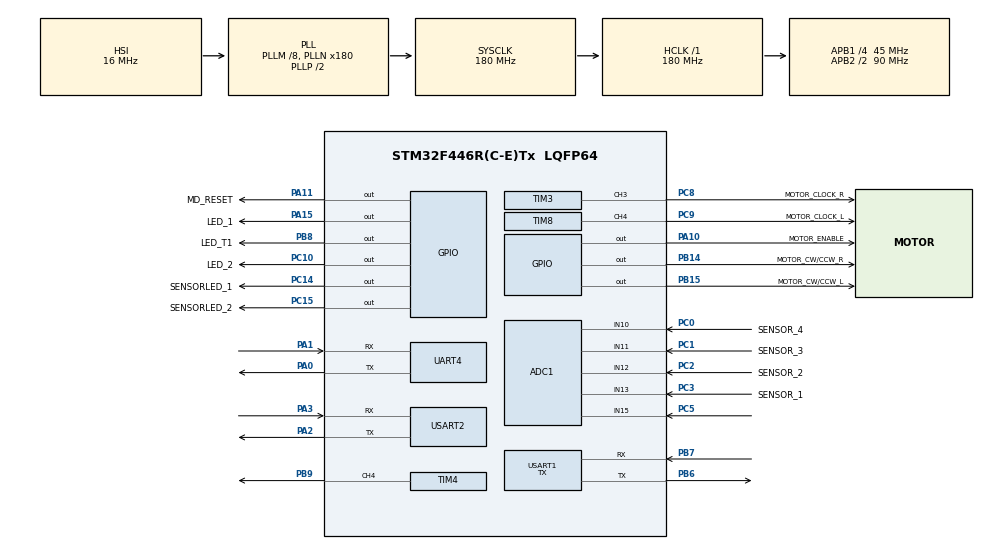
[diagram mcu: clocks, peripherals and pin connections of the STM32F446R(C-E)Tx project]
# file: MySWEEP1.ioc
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ADC1.Channel-0\#ChannelRegularConversion=ADC_CHANNEL_15
ADC1.Channel-1\#ChannelRegularConversion=ADC_CHANNEL_13
ADC1.Channel-2\#ChannelRegularConversion=ADC_CHANNEL_12
ADC1.Channel-3\#ChannelRegularConversion=ADC_CHANNEL_11
ADC1.Channel-4\#ChannelRegularConversion=ADC_CHANNEL_10
ADC1.ContinuousConvMode=ENABLE
ADC1.EnableAnalogWatchDog=false
ADC1.InjNumberOfConversion=0
ADC1.NbrOfConversion=5
ADC1.NbrOfConversionFlag=1
ADC1.Rank-0\#ChannelRegularConversion=1
ADC1.Rank-1\#ChannelRegularConversion=2
ADC1.Rank-2\#ChannelRegularConversion=3
ADC1.Rank-3\#ChannelRegularConversion=4
ADC1.Rank-4\#ChannelRegularConversion=5
ADC1.SamplingTime-0\#ChannelRegularConversion=ADC_SAMPLETIME_3CYCLES
ADC1.SamplingTime-1\#ChannelRegularConversion=ADC_SAMPLETIME_3CYCLES
ADC1.SamplingTime-2\#ChannelRegularConversion=ADC_SAMPLETIME_3CYCLES
ADC1.SamplingTime-3\#ChannelRegularConversion=ADC_SAMPLETIME_3CYCLES
ADC1.SamplingTime-4\#ChannelRegularConversion=ADC_SAMPLETIME_3CYCLES
ADC1.ScanConvMode=ENABLE
ADC1.master=1
Dma.ADC1.0.Direction=DMA_PERIPH_TO_MEMORY
Dma.ADC1.0.FIFOMode=DMA_FIFOMODE_DISABLE
Dma.ADC1.0.Instance=DMA2_Stream0
Dma.ADC1.0.MemDataAlignment=DMA_MDATAALIGN_HALFWORD
Dma.ADC1.0.MemInc=DMA_MINC_ENABLE
Dma.ADC1.0.Mode=DMA_NORMAL
Dma.ADC1.0.PeriphDataAlignment=DMA_PDATAALIGN_HALFWORD
Dma.ADC1.0.PeriphInc=DMA_PINC_DISABLE
Dma.ADC1.0.Priority=DMA_PRIORITY_LOW
Dma.Request0=ADC1
Mcu.Family=STM32F4
Mcu.Name=STM32F446R(C-E)Tx
Mcu.Package=LQFP64
NVIC.ADC_IRQn=true\:0\:0\:false\:false\:true\:true\:true\:true
NVIC.DMA2_Stream0_IRQn=true\:2\:0\:true\:false\:true\:false\:true\:true
NVIC.PriorityGroup=NVIC_PRIORITYGROUP_4
NVIC.TIM3_IRQn=true\:0\:0\:false\:false\:true\:true\:true\:true
NVIC.TIM6_DAC_IRQn=true\:2\:0\:true\:false\:true\:true\:true\:true
NVIC.UART4_IRQn=true\:1\:0\:true\:false\:true\:true\:true\:true
PA0-WKUP.Mode=Asynchronous
PA0-WKUP.Signal=UART4_TX
PA1.Mode=Asynchronous
PA1.Signal=UART4_RX
PA10.GPIO_Label=MOTOR_ENABLE
PA10.Signal=GPIO_Output
PA11.GPIO_Label=MD_RESET
PA11.Signal=GPIO_Output
PA15.GPIO_Label=LED_1
PA15.Signal=GPIO_Output
PA2.Mode=Asynchronous
PA2.Signal=USART2_TX
PA3.Mode=Asynchronous
PA3.Signal=USART2_RX
PB14.GPIO_Label=MOTOR_CW/CCW_R
PB14.Signal=GPIO_Output
PB15.GPIO_Label=MOTOR_CW/CCW_L
PB15.Signal=GPIO_Output
PB6.Mode=Asynchronous
PB6.Signal=USART1_TX
PB7.Mode=Asynchronous
PB7.Signal=USART1_RX
PB8.GPIO_Label=LED_T1
PB8.Signal=GPIO_Output
PB9.Signal=S_TIM4_CH4
PC0.GPIO_Label=SENSOR_4
PC0.Signal=ADCx_IN10
PC1.GPIO_Label=SENSOR_3
PC1.Signal=ADCx_IN11
PC10.GPIO_Label=LED_2
PC10.Signal=GPIO_Output
PC14-OSC32_IN.GPIO_Label=SENSORLED_1
PC14-OSC32_IN.Signal=GPIO_Output
PC15-OSC32_OUT.GPIO_Label=SENSORLED_2
PC15-OSC32_OUT.Signal=GPIO_Output
PC2.GPIO_Label=SENSOR_2
PC2.Signal=ADCx_IN12
PC3.GPIO_Label=SENSOR_1
PC3.Signal=ADCx_IN13
PC5.Signal=ADCx_IN15
PC8.GPIO_Label=MOTOR_CLOCK_R
PC8.Signal=S_TIM3_CH3
PC9.GPIO_Label=MOTOR_CLOCK_L
PC9.Signal=S_TIM8_CH4
PH0-OSC_IN.Mode=HSE-External-Oscillator
PH0-OSC_IN.Signal=RCC_OSC_IN
PH1-OSC_OUT.Mode=HSE-External-Oscillator
PH1-OSC_OUT.Signal=RCC_OSC_OUT
ProjectManager.HeapSize=0x200
ProjectManager.StackSize=0x400
ProjectManager.TargetToolchain=STM32CubeIDE
RCC.AHBFreq_Value=180000000
RCC.APB1CLKDivider=RCC_HCLK_DIV4
RCC.APB1Freq_Value=45000000
RCC.APB1TimFreq_Value=90000000
RCC.APB2CLKDivider=RCC_HCLK_DIV2
RCC.APB2Freq_Value=90000000
RCC.APB2TimFreq_Value=180000000
RCC.CortexFreq_Value=180000000
RCC.HCLKFreq_Value=180000000
RCC.PLLM=8
RCC.PLLN=180
RCC.SYSCLKFreq_VALUE=180000000
RCC.SYSCLKSource=RCC_SYSCLKSOURCE_PLLCLK
RCC.USBFreq_Value=180000000
RCC.VCOOutputFreq_Value=360000000
SH.ADCx_IN10.0=ADC1_IN10,IN10
SH.ADCx_IN11.0=ADC1_IN11,IN11
SH.ADCx_IN12.0=ADC1_IN12,IN12
SH.ADCx_IN13.0=ADC1_IN13,IN13
SH.ADCx_IN15.0=ADC1_IN15,IN15
SH.S_TIM3_CH3.0=TIM3_CH3,PWM Generation3 CH3
SH.S_TIM4_CH4.0=TIM4_CH4,PWM Generation4 CH4
SH.S_TIM8_CH4.0=TIM8_CH4,PWM Generation4 CH4
TIM3.Channel-PWM\ Generation3\ CH3=TIM_CHANNEL_3
TIM3.Period=10000-1
TIM3.Prescaler=8-1
TIM3.Pulse-PWM\ Generation3\ CH3=5000-1
TIM4.Channel-PWM\ Generation4\ CH4=TIM_CHANNEL_4
TIM4.Period=100
TIM6.Period=1000-1
TIM6.Prescaler=90-1
TIM8.Channel-PWM\ Generation4\ CH4=TIM_CHANNEL_4
TIM8.Period=10000-1
TIM8.Prescaler=16-1
TIM8.Pulse-PWM\ Generation4\ CH4=5000-1
UART4.VirtualMode=Asynchronous
USART1.Mode=MODE_TX
USART1.VirtualMode=VM_ASYNC
USART2.VirtualMode=VM_ASYNC
VP_TIM6_VS_ClockSourceINT.Mode=Enable_Timer
board=custom

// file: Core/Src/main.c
/* USER CODE BEGIN Header */
/**
 ******************************************************************************
 * @file           : main.c
 * @brief          : Main program body
 ******************************************************************************
 * @attention
 *
 * Copyright (c) 2026 STMicroelectronics.
 * All rights reserved.
 *
 * This software is licensed under terms that can be found in the LICENSE file
 * in the root directory of this software component.
 * If no LICENSE file comes with this software, it is provided AS-IS.
 *
 ******************************************************************************
 */
/* USER CODE END Header */
#include "main.h"
#include "adc.h"
#include "dma.h"
#include "tim.h"
#include "usart.h"
#include "gpio.h"

/* USER CODE BEGIN Includes */
#include "app.h"
#include "drv_link.h"
/* USER CODE END Includes */

void SystemClock_Config(void);

int main(void)
{

  /* MCU Configuration--------------------------------------------------------*/

  /* Reset of all peripherals, Initializes the Flash interface and the Systick. */
  HAL_Init();

  /* Configure the system clock */
  SystemClock_Config();

  /* Initialize all configured peripherals */
  MX_GPIO_Init();
  MX_DMA_Init();
  MX_ADC1_Init();
  MX_TIM6_Init();
  MX_UART4_Init();
  MX_USART2_UART_Init();
  MX_TIM4_Init();
  MX_USART1_UART_Init();
  MX_TIM3_Init();
  MX_TIM8_Init();
  /* USER CODE BEGIN 2 */
  app_init();
  /* USER CODE END 2 */

  /* Infinite loop */
  /* USER CODE BEGIN WHILE */
  while (1)
  {
    app_loop();
    /* USER CODE END WHILE */

	}
}

void SystemClock_Config(void)
{
  RCC_OscInitTypeDef RCC_OscInitStruct = {0};
  RCC_ClkInitTypeDef RCC_ClkInitStruct = {0};

  /** Configure the main internal regulator output voltage
  */
  __HAL_RCC_PWR_CLK_ENABLE();
  __HAL_PWR_VOLTAGESCALING_CONFIG(PWR_REGULATOR_VOLTAGE_SCALE1);

  /** Initializes the RCC Oscillators according to the specified parameters
  * in the RCC_OscInitTypeDef structure.
  */
  RCC_OscInitStruct.OscillatorType = RCC_OSCILLATORTYPE_HSI;
  RCC_OscInitStruct.HSIState = RCC_HSI_ON;
  RCC_OscInitStruct.HSICalibrationValue = RCC_HSICALIBRATION_DEFAULT;
  RCC_OscInitStruct.PLL.PLLState = RCC_PLL_ON;
  RCC_OscInitStruct.PLL.PLLSource = RCC_PLLSOURCE_HSI;
  RCC_OscInitStruct.PLL.PLLM = 8;
  RCC_OscInitStruct.PLL.PLLN = 180;
  RCC_OscInitStruct.PLL.PLLP = RCC_PLLP_DIV2;
  RCC_OscInitStruct.PLL.PLLQ = 2;
  RCC_OscInitStruct.PLL.PLLR = 2;
  if (HAL_RCC_OscConfig(&RCC_OscInitStruct) != HAL_OK)
  {
    Error_Handler();
  }

  /** Activate the Over-Drive mode
  */
  if (HAL_PWREx_EnableOverDrive() != HAL_OK)
  {
    Error_Handler();
  }

  /** Initializes the CPU, AHB and APB buses clocks
  */
  RCC_ClkInitStruct.ClockType = RCC_CLOCKTYPE_HCLK|RCC_CLOCKTYPE_SYSCLK
                              |RCC_CLOCKTYPE_PCLK1|RCC_CLOCKTYPE_PCLK2;
  RCC_ClkInitStruct.SYSCLKSource = RCC_SYSCLKSOURCE_PLLCLK;
  RCC_ClkInitStruct.AHBCLKDivider = RCC_SYSCLK_DIV1;
  RCC_ClkInitStruct.APB1CLKDivider = RCC_HCLK_DIV4;
  RCC_ClkInitStruct.APB2CLKDivider = RCC_HCLK_DIV2;

  if (HAL_RCC_ClockConfig(&RCC_ClkInitStruct, FLASH_LATENCY_5) != HAL_OK)
  {
    Error_Handler();
  }
}

/* USER CODE BEGIN 4 */
void HAL_UART_RxCpltCallback(UART_HandleTypeDef *huart) {
  if (huart->Instance == UART4) {
    link_on_rx();
  }
}

void HAL_UART_ErrorCallback(UART_HandleTypeDef *huart) {
  if (huart->Instance == UART4) {
    link_on_error();
  }
}

/* USER CODE END 4 */

void Error_Handler(void)
{
	__disable_irq();
	while (1) {
	}
}
